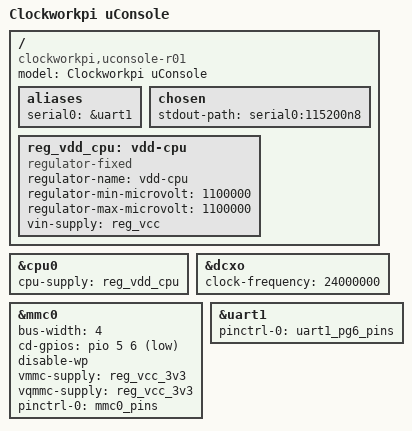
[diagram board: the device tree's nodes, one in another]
// SPDX-License-Identifier: (GPL-2.0+ OR MIT)
// Copyright (C) 2024 Javier Alvarez <javier.alvarez@allthingsembedded.net>

#include <dt-bindings/gpio/gpio.h>
#include <dt-bindings/input/input.h>

/dts-v1/;

#include "sun20i-d1.dtsi"
#include "sun20i-common-regulators.dtsi"

/ {
	model = "Clockworkpi uConsole";
	compatible = "clockworkpi,uconsole-r01", "allwinner,sun20i-d1";

	aliases {
		serial0 = &uart1;
	};

	chosen {
		stdout-path = "serial0:115200n8";
	};

	reg_vdd_cpu: vdd-cpu {
		compatible = "regulator-fixed";
		regulator-name = "vdd-cpu";
		regulator-min-microvolt = <1100000>;
		regulator-max-microvolt = <1100000>;
		vin-supply = <&reg_vcc>;
	};
};

&cpu0 {
	cpu-supply = <&reg_vdd_cpu>;
};

&dcxo {
	clock-frequency = <24000000>;
};

&mmc0 {
	bus-width = <4>;
	cd-gpios = <&pio 5 6 (GPIO_ACTIVE_LOW | GPIO_PULL_UP)>; /* PF6 */
	disable-wp;
	vmmc-supply = <&reg_vcc_3v3>;
	vqmmc-supply = <&reg_vcc_3v3>;
	pinctrl-0 = <&mmc0_pins>;
	pinctrl-names = "default";
	status = "okay";
};

&uart1 {
	pinctrl-0 = <&uart1_pg6_pins>;
	pinctrl-names = "default";
	status = "okay";
};
